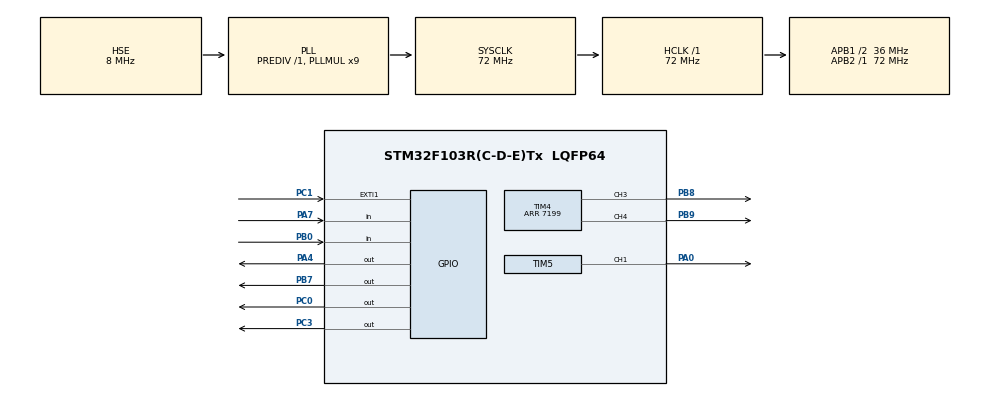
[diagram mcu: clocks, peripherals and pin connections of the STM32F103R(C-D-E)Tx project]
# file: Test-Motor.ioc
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Mcu.Family=STM32F1
Mcu.Name=STM32F103R(C-D-E)Tx
Mcu.Package=LQFP64
NVIC.EXTI1_IRQn=true\:0\:0\:false\:false\:true\:true\:true\:true
NVIC.PriorityGroup=NVIC_PRIORITYGROUP_4
NVIC.TIM2_IRQn=true\:0\:0\:false\:false\:true\:true\:true\:true
PA0-WKUP.Signal=S_TIM5_CH1
PA4.Signal=GPIO_Output
PA7.GPIO_PuPd=GPIO_PULLUP
PA7.Signal=GPIO_Input
PB0.GPIO_PuPd=GPIO_PULLUP
PB0.Signal=GPIO_Input
PB7.Signal=GPIO_Output
PB8.Signal=S_TIM4_CH3
PB9.Signal=S_TIM4_CH4
PC0.Signal=GPIO_Output
PC1.GPIO_PuPd=GPIO_PULLDOWN
PC1.Signal=GPXTI1
PC3.Signal=GPIO_Output
PD0-OSC_IN.Mode=HSE-External-Oscillator
PD0-OSC_IN.Signal=RCC_OSC_IN
PD1-OSC_OUT.Mode=HSE-External-Oscillator
PD1-OSC_OUT.Signal=RCC_OSC_OUT
ProjectManager.HeapSize=0x200
ProjectManager.StackSize=0x400
ProjectManager.TargetToolchain=STM32CubeIDE
RCC.AHBFreq_Value=72000000
RCC.APB1CLKDivider=RCC_HCLK_DIV2
RCC.APB1Freq_Value=36000000
RCC.APB1TimFreq_Value=72000000
RCC.APB2Freq_Value=72000000
RCC.APB2TimFreq_Value=72000000
RCC.HCLKFreq_Value=72000000
RCC.PLLMUL=RCC_PLL_MUL9
RCC.PLLSourceVirtual=RCC_PLLSOURCE_HSE
RCC.SYSCLKFreq_VALUE=72000000
RCC.SYSCLKSource=RCC_SYSCLKSOURCE_PLLCLK
RCC.USBFreq_Value=72000000
SH.S_TIM4_CH3.0=TIM4_CH3,PWM Generation3 CH3
SH.S_TIM4_CH4.0=TIM4_CH4,PWM Generation4 CH4
SH.S_TIM5_CH1.0=TIM5_CH1,PWM Generation1 CH1
TIM2.Period=4999
TIM2.Prescaler=7199
TIM4.Channel-PWM\ Generation3\ CH3=TIM_CHANNEL_3
TIM4.Channel-PWM\ Generation4\ CH4=TIM_CHANNEL_4
TIM4.Period=7199
TIM5.Channel-PWM\ Generation1\ CH1=TIM_CHANNEL_1
TIM5.Period=9999
TIM5.Prescaler=143
VP_SYS_VS_ND.Mode=No_Debug
VP_TIM2_VS_ClockSourceINT.Mode=Internal
VP_TIM4_VS_ClockSourceINT.Mode=Internal
VP_TIM5_VS_ClockSourceINT.Mode=Internal
board=custom

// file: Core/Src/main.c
/* USER CODE BEGIN Header */
/**
  ******************************************************************************
  * @file           : main.c
  * @brief          : Main program body
  ******************************************************************************
  * @attention
  *
  * Copyright (c) 2025 STMicroelectronics.
  * All rights reserved.
  *
  * This software is licensed under terms that can be found in the LICENSE file
  * in the root directory of this software component.
  * If no LICENSE file comes with this software, it is provided AS-IS.
  *
  ******************************************************************************
  */
/* USER CODE END Header */
#include "main.h"
#include "motor.h"
#include "queue.h"
#include "config.h"
#include "servo.h"
#include "beep.h"
#include "ultrasonic.h"

 TIM_HandleTypeDef htim2;
TIM_HandleTypeDef htim4;
TIM_HandleTypeDef htim5;

void SystemClock_Config(void);
static void MX_GPIO_Init(void);
static void MX_TIM2_Init(void);
static void MX_TIM4_Init(void);
static void MX_TIM5_Init(void);

int main(void)
{

  /* MCU Configuration--------------------------------------------------------*/

  /* Reset of all peripherals, Initializes the Flash interface and the Systick. */
  HAL_Init();

  /* Configure the system clock */
  SystemClock_Config();

  /* Initialize all configured peripherals */
  MX_GPIO_Init();
  MX_TIM2_Init();
  MX_TIM4_Init();
    MX_TIM5_Init();
    /* USER CODE BEGIN 2 */

    Motor_Init();
    Beep_Init();
    Servo_Init();
    Ultrasonic_Init();

  /* USER CODE END 2 */

  /* Infinite loop */
  /* USER CODE BEGIN WHILE */
  uint8_t cnt = 0;
  static uint32_t t_servo = 0;
  while (1)
  {
    if(HAL_GetTick() - t_servo >= 50)
    {
      t_servo = HAL_GetTick();
      Servo_SweepStep();
    }

    /* USER CODE END WHILE */

  }
}

void SystemClock_Config(void)
{
  RCC_OscInitTypeDef RCC_OscInitStruct = {0};
  RCC_ClkInitTypeDef RCC_ClkInitStruct = {0};

  /** Initializes the RCC Oscillators according to the specified parameters
  * in the RCC_OscInitTypeDef structure.
  */
  RCC_OscInitStruct.OscillatorType = RCC_OSCILLATORTYPE_HSE;
  RCC_OscInitStruct.HSEState = RCC_HSE_ON;
  RCC_OscInitStruct.HSEPredivValue = RCC_HSE_PREDIV_DIV1;
  RCC_OscInitStruct.HSIState = RCC_HSI_ON;
  RCC_OscInitStruct.PLL.PLLState = RCC_PLL_ON;
  RCC_OscInitStruct.PLL.PLLSource = RCC_PLLSOURCE_HSE;
  RCC_OscInitStruct.PLL.PLLMUL = RCC_PLL_MUL9;
  if (HAL_RCC_OscConfig(&RCC_OscInitStruct) != HAL_OK)
  {
    Error_Handler();
  }

  /** Initializes the CPU, AHB and APB buses clocks
  */
  RCC_ClkInitStruct.ClockType = RCC_CLOCKTYPE_HCLK|RCC_CLOCKTYPE_SYSCLK
                              |RCC_CLOCKTYPE_PCLK1|RCC_CLOCKTYPE_PCLK2;
  RCC_ClkInitStruct.SYSCLKSource = RCC_SYSCLKSOURCE_PLLCLK;
  RCC_ClkInitStruct.AHBCLKDivider = RCC_SYSCLK_DIV1;
  RCC_ClkInitStruct.APB1CLKDivider = RCC_HCLK_DIV2;
  RCC_ClkInitStruct.APB2CLKDivider = RCC_HCLK_DIV1;

  if (HAL_RCC_ClockConfig(&RCC_ClkInitStruct, FLASH_LATENCY_2) != HAL_OK)
  {
    Error_Handler();
  }
}

static void MX_TIM2_Init(void)
{

  TIM_ClockConfigTypeDef sClockSourceConfig = {0};
  TIM_MasterConfigTypeDef sMasterConfig = {0};

  htim2.Instance = TIM2;
  htim2.Init.Prescaler = 7199;
  htim2.Init.CounterMode = TIM_COUNTERMODE_UP;
  htim2.Init.Period = 4999;
  htim2.Init.ClockDivision = TIM_CLOCKDIVISION_DIV1;
  htim2.Init.AutoReloadPreload = TIM_AUTORELOAD_PRELOAD_DISABLE;
  if (HAL_TIM_Base_Init(&htim2) != HAL_OK)
  {
    Error_Handler();
  }
  sClockSourceConfig.ClockSource = TIM_CLOCKSOURCE_INTERNAL;
  if (HAL_TIM_ConfigClockSource(&htim2, &sClockSourceConfig) != HAL_OK)
  {
    Error_Handler();
  }
  sMasterConfig.MasterOutputTrigger = TIM_TRGO_RESET;
  sMasterConfig.MasterSlaveMode = TIM_MASTERSLAVEMODE_DISABLE;
  if (HAL_TIMEx_MasterConfigSynchronization(&htim2, &sMasterConfig) != HAL_OK)
  {
    Error_Handler();
  }

}

static void MX_TIM4_Init(void)
{

  TIM_ClockConfigTypeDef sClockSourceConfig = {0};
  TIM_MasterConfigTypeDef sMasterConfig = {0};
  TIM_OC_InitTypeDef sConfigOC = {0};

  htim4.Instance = TIM4;
  htim4.Init.Prescaler = 0;
  htim4.Init.CounterMode = TIM_COUNTERMODE_UP;
  htim4.Init.Period = 7199;
  htim4.Init.ClockDivision = TIM_CLOCKDIVISION_DIV1;
  htim4.Init.AutoReloadPreload = TIM_AUTORELOAD_PRELOAD_DISABLE;
  if (HAL_TIM_Base_Init(&htim4) != HAL_OK)
  {
    Error_Handler();
  }
  sClockSourceConfig.ClockSource = TIM_CLOCKSOURCE_INTERNAL;
  if (HAL_TIM_ConfigClockSource(&htim4, &sClockSourceConfig) != HAL_OK)
  {
    Error_Handler();
  }
  if (HAL_TIM_PWM_Init(&htim4) != HAL_OK)
  {
    Error_Handler();
  }
  sMasterConfig.MasterOutputTrigger = TIM_TRGO_RESET;
  sMasterConfig.MasterSlaveMode = TIM_MASTERSLAVEMODE_DISABLE;
  if (HAL_TIMEx_MasterConfigSynchronization(&htim4, &sMasterConfig) != HAL_OK)
  {
    Error_Handler();
  }
  sConfigOC.OCMode = TIM_OCMODE_PWM1;
  sConfigOC.Pulse = 0;
  sConfigOC.OCPolarity = TIM_OCPOLARITY_HIGH;
  sConfigOC.OCFastMode = TIM_OCFAST_DISABLE;
  if (HAL_TIM_PWM_ConfigChannel(&htim4, &sConfigOC, TIM_CHANNEL_3) != HAL_OK)
  {
    Error_Handler();
  }
  if (HAL_TIM_PWM_ConfigChannel(&htim4, &sConfigOC, TIM_CHANNEL_4) != HAL_OK)
  {
    Error_Handler();
  }
  HAL_TIM_MspPostInit(&htim4);

}

static void MX_TIM5_Init(void)
{

  TIM_ClockConfigTypeDef sClockSourceConfig = {0};
  TIM_MasterConfigTypeDef sMasterConfig = {0};
  TIM_OC_InitTypeDef sConfigOC = {0};

  htim5.Instance = TIM5;
  htim5.Init.Prescaler = 143;
  htim5.Init.CounterMode = TIM_COUNTERMODE_UP;
  htim5.Init.Period = 9999;
  htim5.Init.ClockDivision = TIM_CLOCKDIVISION_DIV1;
  htim5.Init.AutoReloadPreload = TIM_AUTORELOAD_PRELOAD_DISABLE;
  if (HAL_TIM_Base_Init(&htim5) != HAL_OK)
  {
    Error_Handler();
  }
  sClockSourceConfig.ClockSource = TIM_CLOCKSOURCE_INTERNAL;
  if (HAL_TIM_ConfigClockSource(&htim5, &sClockSourceConfig) != HAL_OK)
  {
    Error_Handler();
  }
  if (HAL_TIM_PWM_Init(&htim5) != HAL_OK)
  {
    Error_Handler();
  }
  sMasterConfig.MasterOutputTrigger = TIM_TRGO_RESET;
  sMasterConfig.MasterSlaveMode = TIM_MASTERSLAVEMODE_DISABLE;
  if (HAL_TIMEx_MasterConfigSynchronization(&htim5, &sMasterConfig) != HAL_OK)
  {
    Error_Handler();
  }
  sConfigOC.OCMode = TIM_OCMODE_PWM1;
  sConfigOC.Pulse = 0;
  sConfigOC.OCPolarity = TIM_OCPOLARITY_HIGH;
  sConfigOC.OCFastMode = TIM_OCFAST_DISABLE;
  if (HAL_TIM_PWM_ConfigChannel(&htim5, &sConfigOC, TIM_CHANNEL_1) != HAL_OK)
  {
    Error_Handler();
  }
  HAL_TIM_MspPostInit(&htim5);

}

static void MX_GPIO_Init(void)
{
  GPIO_InitTypeDef GPIO_InitStruct = {0};

  /* GPIO Ports Clock Enable */
  __HAL_RCC_GPIOD_CLK_ENABLE();
  __HAL_RCC_GPIOC_CLK_ENABLE();
  __HAL_RCC_GPIOA_CLK_ENABLE();
  __HAL_RCC_GPIOB_CLK_ENABLE();

  /*Configure GPIO pin Output Level */
  HAL_GPIO_WritePin(GPIOC, GPIO_PIN_0|GPIO_PIN_3, GPIO_PIN_RESET);

  /*Configure GPIO pin Output Level */
  HAL_GPIO_WritePin(GPIOA, GPIO_PIN_4, GPIO_PIN_RESET);

  /*Configure GPIO pin Output Level */
  HAL_GPIO_WritePin(GPIOB, GPIO_PIN_7, GPIO_PIN_RESET);

  /*Configure GPIO pins : PC0 PC3 */
  GPIO_InitStruct.Pin = GPIO_PIN_0|GPIO_PIN_3;
  GPIO_InitStruct.Mode = GPIO_MODE_OUTPUT_PP;
  GPIO_InitStruct.Pull = GPIO_NOPULL;
  GPIO_InitStruct.Speed = GPIO_SPEED_FREQ_LOW;
  HAL_GPIO_Init(GPIOC, &GPIO_InitStruct);

  /*Configure GPIO pin : PC1 */
  GPIO_InitStruct.Pin = GPIO_PIN_1;
  /*
   * The ECHO pin needs to generate an interrupt on both the rising and
   * falling edges so that ultrasonic distance measurement can start and
   * stop the timer correctly.
   */
  GPIO_InitStruct.Mode = GPIO_MODE_IT_RISING_FALLING;
  GPIO_InitStruct.Pull = GPIO_PULLDOWN;
  HAL_GPIO_Init(GPIOC, &GPIO_InitStruct);

  /*Configure GPIO pin : PA4 */
  GPIO_InitStruct.Pin = GPIO_PIN_4;
  GPIO_InitStruct.Mode = GPIO_MODE_OUTPUT_PP;
  GPIO_InitStruct.Pull = GPIO_NOPULL;
  GPIO_InitStruct.Speed = GPIO_SPEED_FREQ_LOW;
  HAL_GPIO_Init(GPIOA, &GPIO_InitStruct);

  /*Configure GPIO pin : PA7 */
  GPIO_InitStruct.Pin = GPIO_PIN_7;
  GPIO_InitStruct.Mode = GPIO_MODE_INPUT;
  GPIO_InitStruct.Pull = GPIO_PULLUP;
  HAL_GPIO_Init(GPIOA, &GPIO_InitStruct);

  /*Configure GPIO pin : PB0 */
  GPIO_InitStruct.Pin = GPIO_PIN_0;
  GPIO_InitStruct.Mode = GPIO_MODE_INPUT;
  GPIO_InitStruct.Pull = GPIO_PULLUP;
  HAL_GPIO_Init(GPIOB, &GPIO_InitStruct);

  /*Configure GPIO pin : PB7 */
  GPIO_InitStruct.Pin = GPIO_PIN_7;
  GPIO_InitStruct.Mode = GPIO_MODE_OUTPUT_PP;
  GPIO_InitStruct.Pull = GPIO_NOPULL;
  GPIO_InitStruct.Speed = GPIO_SPEED_FREQ_LOW;
  HAL_GPIO_Init(GPIOB, &GPIO_InitStruct);

  /*Configure GPIO pin : PB1 (IR AVOID)*/
  GPIO_InitStruct.Pin = GPIO_PIN_1;
  GPIO_InitStruct.Mode = GPIO_MODE_INPUT;
  GPIO_InitStruct.Pull = GPIO_PULLUP;
  HAL_GPIO_Init(GPIOB, &GPIO_InitStruct);

  /* EXTI interrupt init*/
  HAL_NVIC_SetPriority(EXTI1_IRQn, 0, 0);
  HAL_NVIC_EnableIRQ(EXTI1_IRQn);

}

void Error_Handler(void)
{
  __disable_irq();
  while (1)
  {
  }
}
